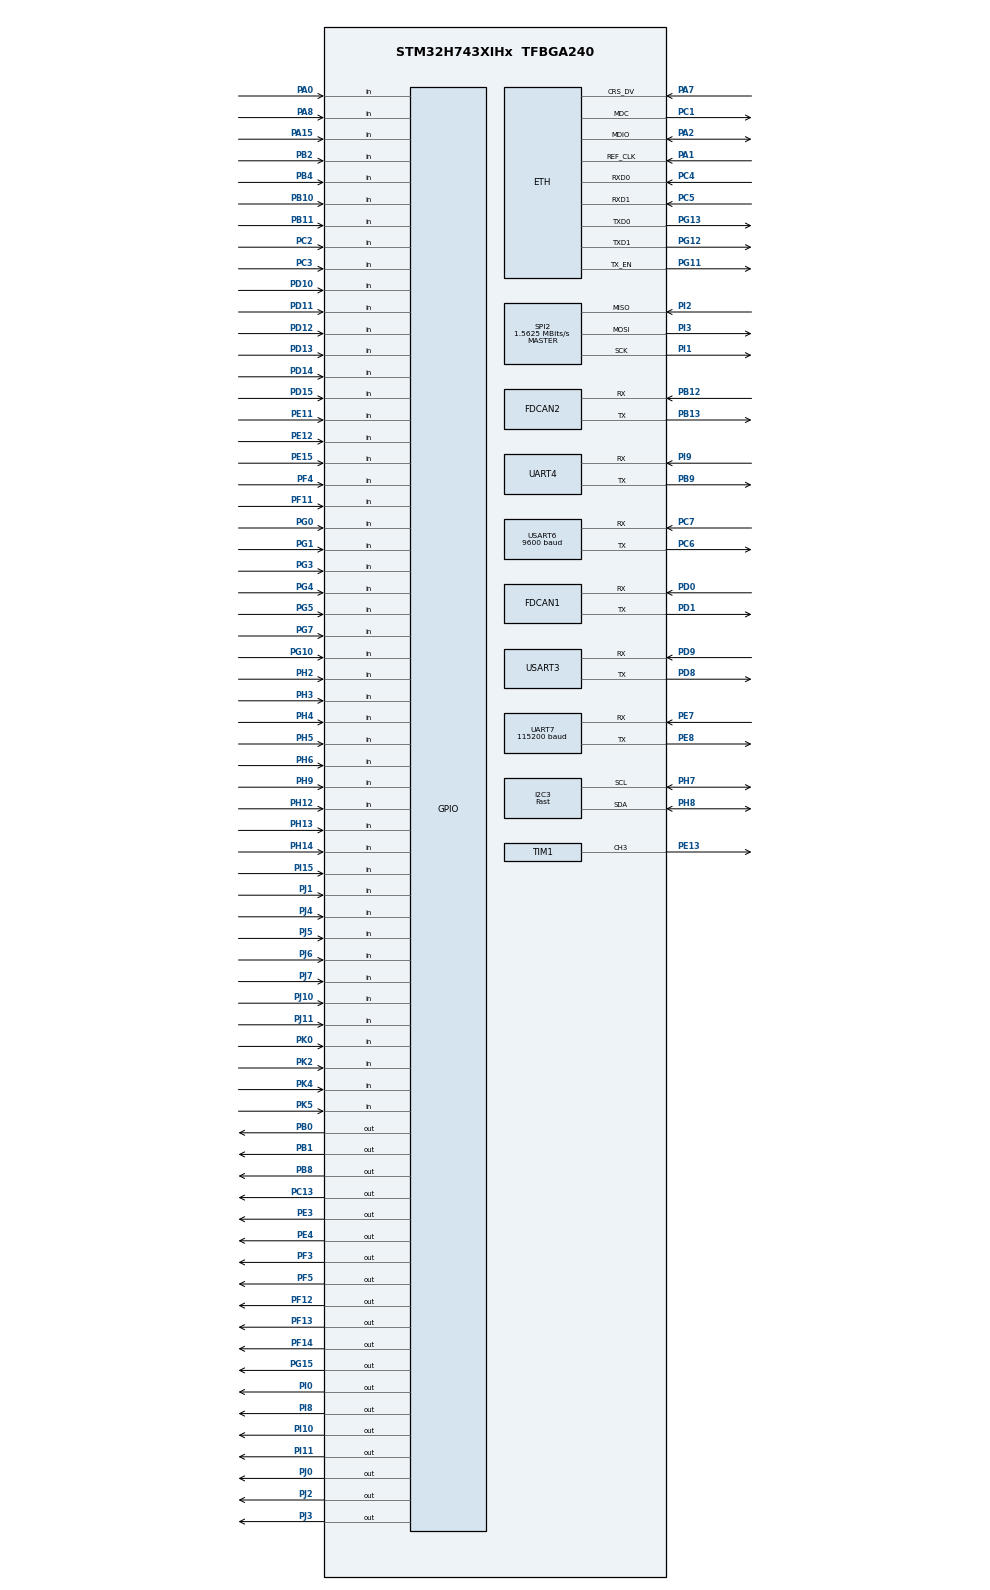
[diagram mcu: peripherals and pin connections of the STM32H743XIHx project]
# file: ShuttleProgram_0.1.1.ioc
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CORTEX_M7.default_mode_Activation=1
Dma.I2C3_TX.0.Direction=DMA_MEMORY_TO_PERIPH
Dma.I2C3_TX.0.EventEnable=DISABLE
Dma.I2C3_TX.0.FIFOMode=DMA_FIFOMODE_DISABLE
Dma.I2C3_TX.0.Instance=DMA1_Stream1
Dma.I2C3_TX.0.MemDataAlignment=DMA_MDATAALIGN_BYTE
Dma.I2C3_TX.0.MemInc=DMA_MINC_ENABLE
Dma.I2C3_TX.0.Mode=DMA_NORMAL
Dma.I2C3_TX.0.PeriphDataAlignment=DMA_PDATAALIGN_BYTE
Dma.I2C3_TX.0.PeriphInc=DMA_PINC_DISABLE
Dma.I2C3_TX.0.Polarity=HAL_DMAMUX_REQ_GEN_RISING
Dma.I2C3_TX.0.Priority=DMA_PRIORITY_LOW
Dma.I2C3_TX.0.RequestNumber=1
Dma.I2C3_TX.0.SignalID=NONE
Dma.I2C3_TX.0.SyncEnable=DISABLE
Dma.I2C3_TX.0.SyncPolarity=HAL_DMAMUX_SYNC_NO_EVENT
Dma.I2C3_TX.0.SyncRequestNumber=1
Dma.I2C3_TX.0.SyncSignalID=NONE
Dma.Request0=I2C3_TX
Dma.Request1=TIM1_CH3
Dma.TIM1_CH3.1.Direction=DMA_MEMORY_TO_PERIPH
Dma.TIM1_CH3.1.EventEnable=DISABLE
Dma.TIM1_CH3.1.FIFOMode=DMA_FIFOMODE_DISABLE
Dma.TIM1_CH3.1.Instance=DMA1_Stream2
Dma.TIM1_CH3.1.MemDataAlignment=DMA_MDATAALIGN_HALFWORD
Dma.TIM1_CH3.1.MemInc=DMA_MINC_ENABLE
Dma.TIM1_CH3.1.Mode=DMA_NORMAL
Dma.TIM1_CH3.1.PeriphDataAlignment=DMA_PDATAALIGN_HALFWORD
Dma.TIM1_CH3.1.PeriphInc=DMA_PINC_DISABLE
Dma.TIM1_CH3.1.Polarity=HAL_DMAMUX_REQ_GEN_RISING
Dma.TIM1_CH3.1.Priority=DMA_PRIORITY_LOW
Dma.TIM1_CH3.1.RequestNumber=1
Dma.TIM1_CH3.1.SignalID=NONE
Dma.TIM1_CH3.1.SyncEnable=DISABLE
Dma.TIM1_CH3.1.SyncPolarity=HAL_DMAMUX_SYNC_NO_EVENT
Dma.TIM1_CH3.1.SyncRequestNumber=1
Dma.TIM1_CH3.1.SyncSignalID=NONE
ETH.MediaInterface=HAL_ETH_RMII_MODE
FDCAN1.CalculateBaudRateNominal=500000
FDCAN1.CalculateTimeBitNominal=2000
FDCAN1.CalculateTimeQuantumNominal=100.0
FDCAN1.ExtFiltersNbr=1
FDCAN1.NominalPrescaler=10
FDCAN1.NominalTimeSeg1=12
FDCAN1.NominalTimeSeg2=7
FDCAN1.ProtocolException=ENABLE
FDCAN1.RxFifo0ElmtsNbr=1
FDCAN1.StdFiltersNbr=1
FDCAN1.TxFifoQueueElmtsNbr=1
FDCAN2.CalculateBaudRateNominal=500000
FDCAN2.CalculateTimeBitNominal=2000
FDCAN2.CalculateTimeQuantumNominal=100.0
FDCAN2.ExtFiltersNbr=1
FDCAN2.NominalPrescaler=10
FDCAN2.NominalTimeSeg1=12
FDCAN2.NominalTimeSeg2=7
FDCAN2.ProtocolException=ENABLE
FDCAN2.RxFifo0ElmtsNbr=1
FDCAN2.StdFiltersNbr=1
FDCAN2.TxFifoQueueElmtsNbr=1
FREERTOS.INCLUDE_xEventGroupSetBitFromISR=1
FREERTOS.Tasks01=mongooseTask,24,2048,StartMongooseTask,Default,NULL,Dynamic,NULL,NULL
FREERTOS.configTOTAL_HEAP_SIZE=131072
FREERTOS.configUSE_NEWLIB_REENTRANT=1
I2C3.I2C_Fall_Time=100
I2C3.I2C_Rise_Time=100
I2C3.I2C_Speed_Mode=I2C_Fast
I2C3.Speed=100
I2C3.Timing=0x5031138C
Mcu.Family=STM32H7
Mcu.Name=STM32H743XIHx
Mcu.Package=TFBGA240
NVIC.DMA1_Stream1_IRQn=true\:5\:0\:false\:false\:true\:true\:false\:true\:true
NVIC.DMA1_Stream2_IRQn=true\:5\:0\:false\:false\:true\:true\:false\:true\:true
NVIC.ETH_IRQn=true\:5\:0\:false\:false\:true\:true\:true\:true\:true
NVIC.FDCAN1_IT0_IRQn=true\:5\:0\:false\:false\:true\:true\:true\:true\:true
NVIC.FDCAN2_IT0_IRQn=true\:5\:0\:false\:false\:true\:true\:true\:true\:true
NVIC.I2C3_EV_IRQn=true\:5\:0\:false\:false\:true\:true\:true\:true\:true
NVIC.PriorityGroup=NVIC_PRIORITYGROUP_4
NVIC.TIM6_DAC_IRQn=true\:15\:0\:false\:false\:true\:false\:false\:true\:true
NVIC.TimeBase=TIM6_DAC_IRQn
NVIC.TimeBaseIP=TIM6
NVIC.UART4_IRQn=true\:5\:0\:false\:false\:true\:true\:true\:true\:true
NVIC.UART7_IRQn=true\:5\:0\:false\:false\:true\:true\:true\:true\:true
NVIC.USART6_IRQn=true\:5\:0\:false\:false\:true\:true\:true\:true\:true
PA0.GPIO_PuPd=GPIO_PULLDOWN
PA0.Signal=GPIO_Input
PA1.GPIO_Speed=GPIO_SPEED_FREQ_VERY_HIGH
PA1.Mode=RMII
PA1.Signal=ETH_REF_CLK
PA15\ (JTDI).Signal=GPIO_Input
PA2.GPIO_Speed=GPIO_SPEED_FREQ_VERY_HIGH
PA2.Mode=RMII
PA2.Signal=ETH_MDIO
PA7.GPIO_Speed=GPIO_SPEED_FREQ_VERY_HIGH
PA7.Mode=RMII
PA7.Signal=ETH_CRS_DV
PA8.Signal=GPIO_Input
PB0.Signal=GPIO_Output
PB1.Signal=GPIO_Output
PB10.GPIO_PuPd=GPIO_PULLDOWN
PB10.Signal=GPIO_Input
PB11.GPIO_PuPd=GPIO_PULLDOWN
PB11.Signal=GPIO_Input
PB12.Mode=FDCAN_Activate
PB12.Signal=FDCAN2_RX
PB13.Mode=FDCAN_Activate
PB13.Signal=FDCAN2_TX
PB2.GPIO_PuPd=GPIO_PULLDOWN
PB2.Signal=GPIO_Input
PB4\ (NJTRST).Signal=GPIO_Input
PB8.Signal=GPIO_Output
PB9.Mode=Asynchronous
PB9.Signal=UART4_TX
PC1.Mode=RMII
PC1.Signal=ETH_MDC
PC13.Signal=GPIO_Output
PC14-OSC32_IN\ (OSC32_IN).Mode=LSE-External-Oscillator
PC14-OSC32_IN\ (OSC32_IN).Signal=RCC_OSC32_IN
PC15-OSC32_OUT\ (OSC32_OUT).Mode=LSE-External-Oscillator
PC15-OSC32_OUT\ (OSC32_OUT).Signal=RCC_OSC32_OUT
PC2.GPIO_PuPd=GPIO_PULLDOWN
PC2.Signal=GPIO_Input
PC3.GPIO_PuPd=GPIO_PULLDOWN
PC3.Signal=GPIO_Input
PC4.GPIO_Speed=GPIO_SPEED_FREQ_VERY_HIGH
PC4.Mode=RMII
PC4.Signal=ETH_RXD0
PC5.GPIO_Speed=GPIO_SPEED_FREQ_VERY_HIGH
PC5.Mode=RMII
PC5.Signal=ETH_RXD1
PC6.Mode=Asynchronous
PC6.Signal=USART6_TX
PC7.Mode=Asynchronous
PC7.Signal=USART6_RX
PD0.Mode=FDCAN_Activate
PD0.Signal=FDCAN1_RX
PD1.Mode=FDCAN_Activate
PD1.Signal=FDCAN1_TX
PD10.Signal=GPIO_Input
PD11.GPIO_PuPd=GPIO_PULLDOWN
PD11.Signal=GPIO_Input
PD12.Signal=GPIO_Input
PD13.Signal=GPIO_Input
PD14.Signal=GPIO_Input
PD15.GPIO_PuPd=GPIO_PULLDOWN
PD15.Signal=GPIO_Input
PD8.Mode=Asynchronous
PD8.Signal=USART3_TX
PD9.Mode=Asynchronous
PD9.Signal=USART3_RX
PE11.Signal=GPIO_Input
PE12.GPIO_PuPd=GPIO_PULLDOWN
PE12.Signal=GPIO_Input
PE13.Signal=S_TIM1_CH3
PE15.Signal=GPIO_Input
PE3.Signal=GPIO_Output
PE4.Signal=GPIO_Output
PE7.Mode=Asynchronous
PE7.Signal=UART7_RX
PE8.Mode=Asynchronous
PE8.Signal=UART7_TX
PF11.GPIO_PuPd=GPIO_PULLDOWN
PF11.Signal=GPIO_Input
PF12.Signal=GPIO_Output
PF13.Signal=GPIO_Output
PF14.Signal=GPIO_Output
PF3.Signal=GPIO_Output
PF4.GPIO_PuPd=GPIO_PULLDOWN
PF4.Signal=GPIO_Input
PF5.Signal=GPIO_Output
PG0.GPIO_PuPd=GPIO_PULLDOWN
PG0.Signal=GPIO_Input
PG1.GPIO_PuPd=GPIO_PULLDOWN
PG1.Signal=GPIO_Input
PG10.GPIO_PuPd=GPIO_PULLDOWN
PG10.Signal=GPIO_Input
PG11.GPIO_Speed=GPIO_SPEED_FREQ_VERY_HIGH
PG11.Mode=RMII
PG11.Signal=ETH_TX_EN
PG12.GPIO_Speed=GPIO_SPEED_FREQ_VERY_HIGH
PG12.Mode=RMII
PG12.Signal=ETH_TXD1
PG13.GPIO_Speed=GPIO_SPEED_FREQ_VERY_HIGH
PG13.Mode=RMII
PG13.Signal=ETH_TXD0
PG15.Signal=GPIO_Output
PG3.Signal=GPIO_Input
PG4.Signal=GPIO_Input
PG5.Signal=GPIO_Input
PG7.Signal=GPIO_Input
PH0-OSC_IN\ (PH0).Mode=HSE-External-Oscillator
PH0-OSC_IN\ (PH0).Signal=RCC_OSC_IN
PH1-OSC_OUT\ (PH1).Mode=HSE-External-Oscillator
PH1-OSC_OUT\ (PH1).Signal=RCC_OSC_OUT
PH12.GPIO_PuPd=GPIO_PULLDOWN
PH12.Signal=GPIO_Input
PH13.Signal=GPIO_Input
PH14.Signal=GPIO_Input
PH2.GPIO_PuPd=GPIO_PULLDOWN
PH2.Signal=GPIO_Input
PH3.GPIO_PuPd=GPIO_PULLDOWN
PH3.Signal=GPIO_Input
PH4.GPIO_PuPd=GPIO_PULLDOWN
PH4.Signal=GPIO_Input
PH5.GPIO_PuPd=GPIO_PULLDOWN
PH5.Signal=GPIO_Input
PH6.GPIO_PuPd=GPIO_PULLDOWN
PH6.Signal=GPIO_Input
PH7.Mode=I2C
PH7.Signal=I2C3_SCL
PH8.Mode=I2C
PH8.Signal=I2C3_SDA
PH9.GPIO_PuPd=GPIO_PULLDOWN
PH9.Signal=GPIO_Input
PI0.Signal=GPIO_Output
PI1.Mode=Full_Duplex_Master
PI1.Signal=SPI2_SCK
PI10.Signal=GPIO_Output
PI11.Signal=GPIO_Output
PI15.GPIO_PuPd=GPIO_PULLDOWN
PI15.Signal=GPIO_Input
PI2.Mode=Full_Duplex_Master
PI2.Signal=SPI2_MISO
PI3.Mode=Full_Duplex_Master
PI3.Signal=SPI2_MOSI
PI8.Signal=GPIO_Output
PI9.Mode=Asynchronous
PI9.Signal=UART4_RX
PJ0.Signal=GPIO_Output
PJ1.GPIO_PuPd=GPIO_PULLDOWN
PJ1.Signal=GPIO_Input
PJ10.Signal=GPIO_Input
PJ11.Signal=GPIO_Input
PJ2.Signal=GPIO_Output
PJ3.Signal=GPIO_Output
PJ4.GPIO_PuPd=GPIO_PULLDOWN
PJ4.Signal=GPIO_Input
PJ5.GPIO_PuPd=GPIO_PULLDOWN
PJ5.Signal=GPIO_Input
PJ6.GPIO_PuPd=GPIO_PULLDOWN
PJ6.Signal=GPIO_Input
PJ7.Signal=GPIO_Input
PK0.Signal=GPIO_Input
PK2.Signal=GPIO_Input
PK4.Signal=GPIO_Input
PK5.GPIO_PuPd=GPIO_PULLDOWN
PK5.Signal=GPIO_Input
ProjectManager.HeapSize=0x200
ProjectManager.StackSize=0x400
ProjectManager.TargetToolchain=STM32CubeIDE
RCC.ADCFreq_Value=50390625
RCC.APB1Freq_Value=100000000
RCC.APB2Freq_Value=100000000
RCC.APB3Freq_Value=100000000
RCC.APB4Freq_Value=100000000
RCC.CortexFreq_Value=400000000
RCC.D1PPRE=RCC_APB3_DIV2
RCC.D2PPRE1=RCC_APB1_DIV2
RCC.D2PPRE2=RCC_APB2_DIV2
RCC.D3PPRE=RCC_APB4_DIV2
RCC.DIVM1=2
RCC.DIVN1=64
RCC.DIVQ1=8
RCC.HCLKFreq_Value=200000000
RCC.HPRE=RCC_HCLK_DIV2
RCC.PLLSourceVirtual=RCC_PLLSOURCE_HSE
RCC.PWR_Regulator_Voltage_Scale=PWR_REGULATOR_VOLTAGE_SCALE0
RCC.SYSCLKFreq_VALUE=400000000
RCC.SYSCLKSource=RCC_SYSCLKSOURCE_PLLCLK
RCC.Spi45ClockSelection=RCC_SPI45CLKSOURCE_HSI
RCC.SupplySource=PWR_LDO_SUPPLY
RCC.USBFreq_Value=100000000
SH.S_TIM1_CH3.0=TIM1_CH3,PWM Generation3 CH3
SPI2.BaudRatePrescaler=SPI_BAUDRATEPRESCALER_64
SPI2.CLKPhase=SPI_PHASE_2EDGE
SPI2.CLKPolarity=SPI_POLARITY_HIGH
SPI2.CalculateBaudRate=1.5625 MBits/s
SPI2.DataSize=SPI_DATASIZE_8BIT
SPI2.Direction=SPI_DIRECTION_2LINES
SPI2.Mode=SPI_MODE_MASTER
SPI2.VirtualType=VM_MASTER
TIM1.Channel-PWM\ Generation3\ CH3=TIM_CHANNEL_3
TIM1.Period=250-1
UART7.BaudRate=115200
USART3.VirtualMode-Asynchronous=VM_ASYNC
USART6.BaudRate=9600
USART6.VirtualMode-Asynchronous=VM_ASYNC
VP_FREERTOS_VS_CMSIS_V2.Mode=CMSIS_V2
VP_MEMORYMAP_VS_MEMORYMAP.Mode=CurAppReg
VP_RNG_VS_RNG.Mode=RNG_Activate
VP_SYS_VS_tim6.Mode=TIM6
VP_TIM1_VS_ClockSourceINT.Mode=Internal
board=custom

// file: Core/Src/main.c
/* USER CODE BEGIN Header */
/**
  ******************************************************************************
  * @file           : main.c
  * @brief          : Main program body
  ******************************************************************************
  * @attention
  *
  * Copyright (c) 2025 STMicroelectronics.
  * All rights reserved.
  *
  * This software is licensed under terms that can be found in the LICENSE file
  * in the root directory of this software component.
  * If no LICENSE file comes with this software, it is provided AS-IS.
  *
  ******************************************************************************
  */
/* USER CODE END Header */
#include "main.h"
#include "string.h"
#include "cmsis_os.h"

/* USER CODE BEGIN Includes */
#include "mongoose_glue.h"
#include "database.h"
#include "sensorSignal.h"
#include "manual.h"
#include "auto.h"
#include "update_data.h"
#include "safety.h"
#include "display.h"
#include "hydraulic.h"
/* USER CODE END Includes */

#if defined ( __ICCARM__ ) /*!< IAR Compiler */
#pragma location=0x30000000
ETH_DMADescTypeDef  DMARxDscrTab[ETH_RX_DESC_CNT]; /* Ethernet Rx DMA Descriptors */
#pragma location=0x30000080
ETH_DMADescTypeDef  DMATxDscrTab[ETH_TX_DESC_CNT]; /* Ethernet Tx DMA Descriptors */

#elif defined ( __CC_ARM )  /* MDK ARM Compiler */

__attribute__((at(0x30000000))) ETH_DMADescTypeDef  DMARxDscrTab[ETH_RX_DESC_CNT]; /* Ethernet Rx DMA Descriptors */
__attribute__((at(0x30000080))) ETH_DMADescTypeDef  DMATxDscrTab[ETH_TX_DESC_CNT]; /* Ethernet Tx DMA Descriptors */

#elif defined ( __GNUC__ ) /* GNU Compiler */

ETH_DMADescTypeDef DMARxDscrTab[ETH_RX_DESC_CNT] __attribute__((section(".RxDescripSection"))); /* Ethernet Rx DMA Descriptors */
ETH_DMADescTypeDef DMATxDscrTab[ETH_TX_DESC_CNT] __attribute__((section(".TxDescripSection")));   /* Ethernet Tx DMA Descriptors */
#endif

ETH_TxPacketConfig TxConfig;

ETH_HandleTypeDef heth;

FDCAN_HandleTypeDef hfdcan1;
FDCAN_HandleTypeDef hfdcan2;

I2C_HandleTypeDef hi2c3;
DMA_HandleTypeDef hdma_i2c3_tx;

RNG_HandleTypeDef hrng;

SPI_HandleTypeDef hspi2;

TIM_HandleTypeDef htim1;
DMA_HandleTypeDef hdma_tim1_ch3;

UART_HandleTypeDef huart4;
UART_HandleTypeDef huart7;
UART_HandleTypeDef huart3;
UART_HandleTypeDef huart6;

/* Definitions for mongooseTask */
osThreadId_t mongooseTaskHandle;
const osThreadAttr_t mongooseTask_attributes = {
  .name = "mongooseTask",
  .stack_size = 2048 * 4,
  .priority = (osPriority_t) osPriorityNormal,
};

void SystemClock_Config(void);
static void MPU_Config(void);
static void MX_GPIO_Init(void);
static void MX_DMA_Init(void);
static void MX_RNG_Init(void);
static void MX_USART3_UART_Init(void);
static void MX_ETH_Init(void);
static void MX_FDCAN1_Init(void);
static void MX_UART7_Init(void);
static void MX_I2C3_Init(void);
static void MX_TIM1_Init(void);
static void MX_USART6_UART_Init(void);
static void MX_SPI2_Init(void);
static void MX_UART4_Init(void);
static void MX_FDCAN2_Init(void);
void StartMongooseTask(void *argument);

/* USER CODE BEGIN PFP */
void selectMode(uint8_t sw)
{
	static bool run_one = false ;
	if(!run_one){
		manualTaskInit();
		autoTaskInit() ;
		dataUpdateTaskInit();
		safetyTaskInit();
		hydraulicTaskInit();
		run_one = true ;
		return ;
	}
	if(sw)
	{
		manualTaskSupend();
		autoTaskResume() ;
	}else
	{
		autoTaskSupend();
		manualTaskResume();
	}
	static uint8_t current_mode;
	if (current_mode != sw) {
		ResetOutput();
		SetSpeed(0, SetSpeedPDO[0]);
		current_mode = sw;
	}

}
/* USER CODE END PFP */

/* USER CODE BEGIN 0 */
int _write(int fd, unsigned char *buf, int len) {
  if (fd == 1 || fd == 2) {                     // stdout or stderr ?
    HAL_UART_Transmit(&huart3, buf, len, 999);  // Print to the UART
  }
  return len;
}
bool mg_random(void *buf, size_t len) {  // Use on-board RNG
  for (size_t n = 0; n < len; n += sizeof(uint32_t)) {
    uint32_t r;
    HAL_RNG_GenerateRandomNumber(&hrng, &r);
    memcpy((char *) buf + n, &r, n + sizeof(r) > len ? len - n : sizeof(r));
  }
  return true; // TODO(): ensure successful RNG init, then return on false above
}
/* USER CODE END 0 */

int main(void)
{

  /* MPU Configuration--------------------------------------------------------*/
  MPU_Config();

  /* MCU Configuration--------------------------------------------------------*/

  /* Reset of all peripherals, Initializes the Flash interface and the Systick. */
  HAL_Init();

  /* Configure the system clock */
  SystemClock_Config();

  /* Initialize all configured peripherals */
  MX_GPIO_Init();
  MX_DMA_Init();
  MX_RNG_Init();
  MX_USART3_UART_Init();
  MX_ETH_Init();
  MX_FDCAN1_Init();
  MX_UART7_Init();
  MX_I2C3_Init();
  MX_TIM1_Init();
  MX_USART6_UART_Init();
  MX_SPI2_Init();
  MX_UART4_Init();
  MX_FDCAN2_Init();
  /* USER CODE BEGIN 2 */
  switch_mode_register_callback(selectMode);

  /* USER CODE END 2 */

  /* Init scheduler */
  osKernelInitialize();

  /* USER CODE BEGIN RTOS_QUEUES */
  /* add queues, ... */

  /*
   * Priority task default
   * Auto task-------------osPriorityNormal3
   * Manual task-----------osPriorityNormal3
   * inforUpdatetask-------osPriorityNormal2
   * displayTaskHandle-----osPriorityNormal1
   * StartMongooseTask-----------osPriorityNormal
   * DataEthTask-----------osPriorityAboveNormal
   * IOTaskHandle----------osPriorityAboveNormal1
   * hydraulicTaskAttr-----osPriorityAboveNormal2
   * safetyTaskHandle------osPriorityAboveNormal3
   * qrTask----------------osPriorityISR
   */
  displayInit();
  databaseInit();
  sensorTaskInit();
  /* USER CODE END RTOS_QUEUES */

  /* Create the thread(s) */
  /* creation of mongooseTask */
  mongooseTaskHandle = osThreadNew(StartMongooseTask, NULL, &mongooseTask_attributes);

  /* Start scheduler */
  osKernelStart();

  /* We should never get here as control is now taken by the scheduler */

  /* Infinite loop */
  while (1)
  {

  }
}

void SystemClock_Config(void)
{
  RCC_OscInitTypeDef RCC_OscInitStruct = {0};
  RCC_ClkInitTypeDef RCC_ClkInitStruct = {0};

  /** Supply configuration update enable
  */
  HAL_PWREx_ConfigSupply(PWR_LDO_SUPPLY);

  /** Configure the main internal regulator output voltage
  */
  __HAL_PWR_VOLTAGESCALING_CONFIG(PWR_REGULATOR_VOLTAGE_SCALE0);

  while(!__HAL_PWR_GET_FLAG(PWR_FLAG_VOSRDY)) {}

  /** Initializes the RCC Oscillators according to the specified parameters
  * in the RCC_OscInitTypeDef structure.
  */
  RCC_OscInitStruct.OscillatorType = RCC_OSCILLATORTYPE_HSI48|RCC_OSCILLATORTYPE_HSE;
  RCC_OscInitStruct.HSEState = RCC_HSE_ON;
  RCC_OscInitStruct.HSI48State = RCC_HSI48_ON;
  RCC_OscInitStruct.PLL.PLLState = RCC_PLL_ON;
  RCC_OscInitStruct.PLL.PLLSource = RCC_PLLSOURCE_HSE;
  RCC_OscInitStruct.PLL.PLLM = 2;
  RCC_OscInitStruct.PLL.PLLN = 64;
  RCC_OscInitStruct.PLL.PLLP = 2;
  RCC_OscInitStruct.PLL.PLLQ = 8;
  RCC_OscInitStruct.PLL.PLLR = 2;
  RCC_OscInitStruct.PLL.PLLRGE = RCC_PLL1VCIRANGE_3;
  RCC_OscInitStruct.PLL.PLLVCOSEL = RCC_PLL1VCOWIDE;
  RCC_OscInitStruct.PLL.PLLFRACN = 0;
  if (HAL_RCC_OscConfig(&RCC_OscInitStruct) != HAL_OK)
  {
    Error_Handler();
  }

  /** Initializes the CPU, AHB and APB buses clocks
  */
  RCC_ClkInitStruct.ClockType = RCC_CLOCKTYPE_HCLK|RCC_CLOCKTYPE_SYSCLK
                              |RCC_CLOCKTYPE_PCLK1|RCC_CLOCKTYPE_PCLK2
                              |RCC_CLOCKTYPE_D3PCLK1|RCC_CLOCKTYPE_D1PCLK1;
  RCC_ClkInitStruct.SYSCLKSource = RCC_SYSCLKSOURCE_PLLCLK;
  RCC_ClkInitStruct.SYSCLKDivider = RCC_SYSCLK_DIV1;
  RCC_ClkInitStruct.AHBCLKDivider = RCC_HCLK_DIV2;
  RCC_ClkInitStruct.APB3CLKDivider = RCC_APB3_DIV2;
  RCC_ClkInitStruct.APB1CLKDivider = RCC_APB1_DIV2;
  RCC_ClkInitStruct.APB2CLKDivider = RCC_APB2_DIV2;
  RCC_ClkInitStruct.APB4CLKDivider = RCC_APB4_DIV2;

  if (HAL_RCC_ClockConfig(&RCC_ClkInitStruct, FLASH_LATENCY_2) != HAL_OK)
  {
    Error_Handler();
  }
}

static void MX_ETH_Init(void)
{

   static uint8_t MACAddr[6];

  heth.Instance = ETH;
  MACAddr[0] = 0x00;
  MACAddr[1] = 0x80;
  MACAddr[2] = 0xE1;
  MACAddr[3] = 0x00;
  MACAddr[4] = 0x00;
  MACAddr[5] = 0x00;
  heth.Init.MACAddr = &MACAddr[0];
  heth.Init.MediaInterface = HAL_ETH_RMII_MODE;
  heth.Init.TxDesc = DMATxDscrTab;
  heth.Init.RxDesc = DMARxDscrTab;
  heth.Init.RxBuffLen = 1536;

  if (HAL_ETH_Init(&heth) != HAL_OK)
  {
    Error_Handler();
  }

  memset(&TxConfig, 0 , sizeof(ETH_TxPacketConfig));
  TxConfig.Attributes = ETH_TX_PACKETS_FEATURES_CSUM | ETH_TX_PACKETS_FEATURES_CRCPAD;
  TxConfig.ChecksumCtrl = ETH_CHECKSUM_IPHDR_PAYLOAD_INSERT_PHDR_CALC;
  TxConfig.CRCPadCtrl = ETH_CRC_PAD_INSERT;

}

static void MX_FDCAN1_Init(void)
{

  hfdcan1.Instance = FDCAN1;
  hfdcan1.Init.FrameFormat = FDCAN_FRAME_CLASSIC;
  hfdcan1.Init.Mode = FDCAN_MODE_NORMAL;
  hfdcan1.Init.AutoRetransmission = DISABLE;
  hfdcan1.Init.TransmitPause = DISABLE;
  hfdcan1.Init.ProtocolException = ENABLE;
  hfdcan1.Init.NominalPrescaler = 10;
  hfdcan1.Init.NominalSyncJumpWidth = 1;
  hfdcan1.Init.NominalTimeSeg1 = 12;
  hfdcan1.Init.NominalTimeSeg2 = 7;
  hfdcan1.Init.DataPrescaler = 1;
  hfdcan1.Init.DataSyncJumpWidth = 1;
  hfdcan1.Init.DataTimeSeg1 = 1;
  hfdcan1.Init.DataTimeSeg2 = 1;
  hfdcan1.Init.MessageRAMOffset = 0;
  hfdcan1.Init.StdFiltersNbr = 1;
  hfdcan1.Init.ExtFiltersNbr = 1;
  hfdcan1.Init.RxFifo0ElmtsNbr = 1;
  hfdcan1.Init.RxFifo0ElmtSize = FDCAN_DATA_BYTES_8;
  hfdcan1.Init.RxFifo1ElmtsNbr = 0;
  hfdcan1.Init.RxFifo1ElmtSize = FDCAN_DATA_BYTES_8;
  hfdcan1.Init.RxBuffersNbr = 0;
  hfdcan1.Init.RxBufferSize = FDCAN_DATA_BYTES_8;
  hfdcan1.Init.TxEventsNbr = 0;
  hfdcan1.Init.TxBuffersNbr = 0;
  hfdcan1.Init.TxFifoQueueElmtsNbr = 1;
  hfdcan1.Init.TxFifoQueueMode = FDCAN_TX_FIFO_OPERATION;
  hfdcan1.Init.TxElmtSize = FDCAN_DATA_BYTES_8;
  if (HAL_FDCAN_Init(&hfdcan1) != HAL_OK)
  {
    Error_Handler();
  }

}

static void MX_FDCAN2_Init(void)
{

  hfdcan2.Instance = FDCAN2;
  hfdcan2.Init.FrameFormat = FDCAN_FRAME_CLASSIC;
  hfdcan2.Init.Mode = FDCAN_MODE_NORMAL;
  hfdcan2.Init.AutoRetransmission = DISABLE;
  hfdcan2.Init.TransmitPause = DISABLE;
  hfdcan2.Init.ProtocolException = ENABLE;
  hfdcan2.Init.NominalPrescaler = 10;
  hfdcan2.Init.NominalSyncJumpWidth = 1;
  hfdcan2.Init.NominalTimeSeg1 = 12;
  hfdcan2.Init.NominalTimeSeg2 = 7;
  hfdcan2.Init.DataPrescaler = 1;
  hfdcan2.Init.DataSyncJumpWidth = 1;
  hfdcan2.Init.DataTimeSeg1 = 1;
  hfdcan2.Init.DataTimeSeg2 = 1;
  hfdcan2.Init.MessageRAMOffset = 0;
  hfdcan2.Init.StdFiltersNbr = 1;
  hfdcan2.Init.ExtFiltersNbr = 1;
  hfdcan2.Init.RxFifo0ElmtsNbr = 1;
  hfdcan2.Init.RxFifo0ElmtSize = FDCAN_DATA_BYTES_8;
  hfdcan2.Init.RxFifo1ElmtsNbr = 0;
  hfdcan2.Init.RxFifo1ElmtSize = FDCAN_DATA_BYTES_8;
  hfdcan2.Init.RxBuffersNbr = 0;
  hfdcan2.Init.RxBufferSize = FDCAN_DATA_BYTES_8;
  hfdcan2.Init.TxEventsNbr = 0;
  hfdcan2.Init.TxBuffersNbr = 0;
  hfdcan2.Init.TxFifoQueueElmtsNbr = 1;
  hfdcan2.Init.TxFifoQueueMode = FDCAN_TX_FIFO_OPERATION;
  hfdcan2.Init.TxElmtSize = FDCAN_DATA_BYTES_8;
  if (HAL_FDCAN_Init(&hfdcan2) != HAL_OK)
  {
    Error_Handler();
  }

}

static void MX_I2C3_Init(void)
{

  hi2c3.Instance = I2C3;
  hi2c3.Init.Timing = 0x5031138C;
  hi2c3.Init.OwnAddress1 = 0;
  hi2c3.Init.AddressingMode = I2C_ADDRESSINGMODE_7BIT;
  hi2c3.Init.DualAddressMode = I2C_DUALADDRESS_DISABLE;
  hi2c3.Init.OwnAddress2 = 0;
  hi2c3.Init.OwnAddress2Masks = I2C_OA2_NOMASK;
  hi2c3.Init.GeneralCallMode = I2C_GENERALCALL_DISABLE;
  hi2c3.Init.NoStretchMode = I2C_NOSTRETCH_DISABLE;
  if (HAL_I2C_Init(&hi2c3) != HAL_OK)
  {
    Error_Handler();
  }

  /** Configure Analogue filter
  */
  if (HAL_I2CEx_ConfigAnalogFilter(&hi2c3, I2C_ANALOGFILTER_ENABLE) != HAL_OK)
  {
    Error_Handler();
  }

  /** Configure Digital filter
  */
  if (HAL_I2CEx_ConfigDigitalFilter(&hi2c3, 0) != HAL_OK)
  {
    Error_Handler();
  }

}

static void MX_RNG_Init(void)
{

  hrng.Instance = RNG;
  hrng.Init.ClockErrorDetection = RNG_CED_ENABLE;
  if (HAL_RNG_Init(&hrng) != HAL_OK)
  {
    Error_Handler();
  }

}

static void MX_SPI2_Init(void)
{

  /* SPI2 parameter configuration*/
  hspi2.Instance = SPI2;
  hspi2.Init.Mode = SPI_MODE_MASTER;
  hspi2.Init.Direction = SPI_DIRECTION_2LINES;
  hspi2.Init.DataSize = SPI_DATASIZE_8BIT;
  hspi2.Init.CLKPolarity = SPI_POLARITY_HIGH;
  hspi2.Init.CLKPhase = SPI_PHASE_2EDGE;
  hspi2.Init.NSS = SPI_NSS_SOFT;
  hspi2.Init.BaudRatePrescaler = SPI_BAUDRATEPRESCALER_64;
  hspi2.Init.FirstBit = SPI_FIRSTBIT_MSB;
  hspi2.Init.TIMode = SPI_TIMODE_DISABLE;
  hspi2.Init.CRCCalculation = SPI_CRCCALCULATION_DISABLE;
  hspi2.Init.CRCPolynomial = 0x0;
  hspi2.Init.NSSPMode = SPI_NSS_PULSE_ENABLE;
  hspi2.Init.NSSPolarity = SPI_NSS_POLARITY_LOW;
  hspi2.Init.FifoThreshold = SPI_FIFO_THRESHOLD_01DATA;
  hspi2.Init.TxCRCInitializationPattern = SPI_CRC_INITIALIZATION_ALL_ZERO_PATTERN;
  hspi2.Init.RxCRCInitializationPattern = SPI_CRC_INITIALIZATION_ALL_ZERO_PATTERN;
  hspi2.Init.MasterSSIdleness = SPI_MASTER_SS_IDLENESS_00CYCLE;
  hspi2.Init.MasterInterDataIdleness = SPI_MASTER_INTERDATA_IDLENESS_00CYCLE;
  hspi2.Init.MasterReceiverAutoSusp = SPI_MASTER_RX_AUTOSUSP_DISABLE;
  hspi2.Init.MasterKeepIOState = SPI_MASTER_KEEP_IO_STATE_DISABLE;
  hspi2.Init.IOSwap = SPI_IO_SWAP_DISABLE;
  if (HAL_SPI_Init(&hspi2) != HAL_OK)
  {
    Error_Handler();
  }

}

static void MX_TIM1_Init(void)
{

  TIM_ClockConfigTypeDef sClockSourceConfig = {0};
  TIM_MasterConfigTypeDef sMasterConfig = {0};
  TIM_OC_InitTypeDef sConfigOC = {0};
  TIM_BreakDeadTimeConfigTypeDef sBreakDeadTimeConfig = {0};

  htim1.Instance = TIM1;
  htim1.Init.Prescaler = 0;
  htim1.Init.CounterMode = TIM_COUNTERMODE_UP;
  htim1.Init.Period = 250-1;
  htim1.Init.ClockDivision = TIM_CLOCKDIVISION_DIV1;
  htim1.Init.RepetitionCounter = 0;
  htim1.Init.AutoReloadPreload = TIM_AUTORELOAD_PRELOAD_DISABLE;
  if (HAL_TIM_Base_Init(&htim1) != HAL_OK)
  {
    Error_Handler();
  }
  sClockSourceConfig.ClockSource = TIM_CLOCKSOURCE_INTERNAL;
  if (HAL_TIM_ConfigClockSource(&htim1, &sClockSourceConfig) != HAL_OK)
  {
    Error_Handler();
  }
  if (HAL_TIM_PWM_Init(&htim1) != HAL_OK)
  {
    Error_Handler();
  }
  sMasterConfig.MasterOutputTrigger = TIM_TRGO_RESET;
  sMasterConfig.MasterOutputTrigger2 = TIM_TRGO2_RESET;
  sMasterConfig.MasterSlaveMode = TIM_MASTERSLAVEMODE_DISABLE;
  if (HAL_TIMEx_MasterConfigSynchronization(&htim1, &sMasterConfig) != HAL_OK)
  {
    Error_Handler();
  }
  sConfigOC.OCMode = TIM_OCMODE_PWM1;
  sConfigOC.Pulse = 0;
  sConfigOC.OCPolarity = TIM_OCPOLARITY_HIGH;
  sConfigOC.OCNPolarity = TIM_OCNPOLARITY_HIGH;
  sConfigOC.OCFastMode = TIM_OCFAST_DISABLE;
  sConfigOC.OCIdleState = TIM_OCIDLESTATE_RESET;
  sConfigOC.OCNIdleState = TIM_OCNIDLESTATE_RESET;
  if (HAL_TIM_PWM_ConfigChannel(&htim1, &sConfigOC, TIM_CHANNEL_3) != HAL_OK)
  {
    Error_Handler();
  }
  sBreakDeadTimeConfig.OffStateRunMode = TIM_OSSR_DISABLE;
  sBreakDeadTimeConfig.OffStateIDLEMode = TIM_OSSI_DISABLE;
  sBreakDeadTimeConfig.LockLevel = TIM_LOCKLEVEL_OFF;
  sBreakDeadTimeConfig.DeadTime = 0;
  sBreakDeadTimeConfig.BreakState = TIM_BREAK_DISABLE;
  sBreakDeadTimeConfig.BreakPolarity = TIM_BREAKPOLARITY_HIGH;
  sBreakDeadTimeConfig.BreakFilter = 0;
  sBreakDeadTimeConfig.Break2State = TIM_BREAK2_DISABLE;
  sBreakDeadTimeConfig.Break2Polarity = TIM_BREAK2POLARITY_HIGH;
  sBreakDeadTimeConfig.Break2Filter = 0;
  sBreakDeadTimeConfig.AutomaticOutput = TIM_AUTOMATICOUTPUT_DISABLE;
  if (HAL_TIMEx_ConfigBreakDeadTime(&htim1, &sBreakDeadTimeConfig) != HAL_OK)
  {
    Error_Handler();
  }
  HAL_TIM_MspPostInit(&htim1);

}

static void MX_UART4_Init(void)
{

  huart4.Instance = UART4;
  huart4.Init.BaudRate = 115200;
  huart4.Init.WordLength = UART_WORDLENGTH_8B;
  huart4.Init.StopBits = UART_STOPBITS_1;
  huart4.Init.Parity = UART_PARITY_NONE;
  huart4.Init.Mode = UART_MODE_TX_RX;
  huart4.Init.HwFlowCtl = UART_HWCONTROL_NONE;
  huart4.Init.OverSampling = UART_OVERSAMPLING_16;
  huart4.Init.OneBitSampling = UART_ONE_BIT_SAMPLE_DISABLE;
  huart4.Init.ClockPrescaler = UART_PRESCALER_DIV1;
  huart4.AdvancedInit.AdvFeatureInit = UART_ADVFEATURE_NO_INIT;
  if (HAL_UART_Init(&huart4) != HAL_OK)
  {
    Error_Handler();
  }
  if (HAL_UARTEx_SetTxFifoThreshold(&huart4, UART_TXFIFO_THRESHOLD_1_8) != HAL_OK)
  {
    Error_Handler();
  }
  if (HAL_UARTEx_SetRxFifoThreshold(&huart4, UART_RXFIFO_THRESHOLD_1_8) != HAL_OK)
  {
    Error_Handler();
  }
  if (HAL_UARTEx_DisableFifoMode(&huart4) != HAL_OK)
  {
    Error_Handler();
  }

}

static void MX_UART7_Init(void)
{

  huart7.Instance = UART7;
  huart7.Init.BaudRate = 115200;
  huart7.Init.WordLength = UART_WORDLENGTH_8B;
  huart7.Init.StopBits = UART_STOPBITS_1;
  huart7.Init.Parity = UART_PARITY_NONE;
  huart7.Init.Mode = UART_MODE_TX_RX;
  huart7.Init.HwFlowCtl = UART_HWCONTROL_NONE;
  huart7.Init.OverSampling = UART_OVERSAMPLING_16;
  huart7.Init.OneBitSampling = UART_ONE_BIT_SAMPLE_DISABLE;
  huart7.Init.ClockPrescaler = UART_PRESCALER_DIV1;
  huart7.AdvancedInit.AdvFeatureInit = UART_ADVFEATURE_NO_INIT;
  if (HAL_UART_Init(&huart7) != HAL_OK)
  {
    Error_Handler();
  }
  if (HAL_UARTEx_SetTxFifoThreshold(&huart7, UART_TXFIFO_THRESHOLD_1_8) != HAL_OK)
  {
    Error_Handler();
  }
  if (HAL_UARTEx_SetRxFifoThreshold(&huart7, UART_RXFIFO_THRESHOLD_1_8) != HAL_OK)
  {
    Error_Handler();
  }
  if (HAL_UARTEx_DisableFifoMode(&huart7) != HAL_OK)
  {
    Error_Handler();
  }

}

static void MX_USART3_UART_Init(void)
{

  huart3.Instance = USART3;
  huart3.Init.BaudRate = 115200;
  huart3.Init.WordLength = UART_WORDLENGTH_8B;
  huart3.Init.StopBits = UART_STOPBITS_1;
  huart3.Init.Parity = UART_PARITY_NONE;
  huart3.Init.Mode = UART_MODE_TX_RX;
  huart3.Init.HwFlowCtl = UART_HWCONTROL_NONE;
  huart3.Init.OverSampling = UART_OVERSAMPLING_16;
  huart3.Init.OneBitSampling = UART_ONE_BIT_SAMPLE_DISABLE;
  huart3.Init.ClockPrescaler = UART_PRESCALER_DIV1;
  huart3.AdvancedInit.AdvFeatureInit = UART_ADVFEATURE_NO_INIT;
  if (HAL_UART_Init(&huart3) != HAL_OK)
  {
    Error_Handler();
  }
  if (HAL_UARTEx_SetTxFifoThreshold(&huart3, UART_TXFIFO_THRESHOLD_1_8) != HAL_OK)
  {
    Error_Handler();
  }
  if (HAL_UARTEx_SetRxFifoThreshold(&huart3, UART_RXFIFO_THRESHOLD_1_8) != HAL_OK)
  {
    Error_Handler();
  }
  if (HAL_UARTEx_DisableFifoMode(&huart3) != HAL_OK)
  {
    Error_Handler();
  }

}

static void MX_USART6_UART_Init(void)
{

  huart6.Instance = USART6;
  huart6.Init.BaudRate = 9600;
  huart6.Init.WordLength = UART_WORDLENGTH_8B;
  huart6.Init.StopBits = UART_STOPBITS_1;
  huart6.Init.Parity = UART_PARITY_NONE;
  huart6.Init.Mode = UART_MODE_TX_RX;
  huart6.Init.HwFlowCtl = UART_HWCONTROL_NONE;
  huart6.Init.OverSampling = UART_OVERSAMPLING_16;
  huart6.Init.OneBitSampling = UART_ONE_BIT_SAMPLE_DISABLE;
  huart6.Init.ClockPrescaler = UART_PRESCALER_DIV1;
  huart6.AdvancedInit.AdvFeatureInit = UART_ADVFEATURE_NO_INIT;
  if (HAL_UART_Init(&huart6) != HAL_OK)
  {
    Error_Handler();
  }
  if (HAL_UARTEx_SetTxFifoThreshold(&huart6, UART_TXFIFO_THRESHOLD_1_8) != HAL_OK)
  {
    Error_Handler();
  }
  if (HAL_UARTEx_SetRxFifoThreshold(&huart6, UART_RXFIFO_THRESHOLD_1_8) != HAL_OK)
  {
    Error_Handler();
  }
  if (HAL_UARTEx_DisableFifoMode(&huart6) != HAL_OK)
  {
    Error_Handler();
  }

}

static void MX_DMA_Init(void)
{

  /* DMA controller clock enable */
  __HAL_RCC_DMA1_CLK_ENABLE();

  /* DMA interrupt init */
  /* DMA1_Stream1_IRQn interrupt configuration */
  HAL_NVIC_SetPriority(DMA1_Stream1_IRQn, 5, 0);
  HAL_NVIC_EnableIRQ(DMA1_Stream1_IRQn);
  /* DMA1_Stream2_IRQn interrupt configuration */
  HAL_NVIC_SetPriority(DMA1_Stream2_IRQn, 5, 0);
  HAL_NVIC_EnableIRQ(DMA1_Stream2_IRQn);

}

static void MX_GPIO_Init(void)
{
  GPIO_InitTypeDef GPIO_InitStruct = {0};

  /* GPIO Ports Clock Enable */
  __HAL_RCC_GPIOK_CLK_ENABLE();
  __HAL_RCC_GPIOG_CLK_ENABLE();
  __HAL_RCC_GPIOA_CLK_ENABLE();
  __HAL_RCC_GPIOI_CLK_ENABLE();
  __HAL_RCC_GPIOB_CLK_ENABLE();
  __HAL_RCC_GPIOH_CLK_ENABLE();
  __HAL_RCC_GPIOC_CLK_ENABLE();
  __HAL_RCC_GPIOE_CLK_ENABLE();
  __HAL_RCC_GPIOD_CLK_ENABLE();
  __HAL_RCC_GPIOF_CLK_ENABLE();
  __HAL_RCC_GPIOJ_CLK_ENABLE();

  /*Configure GPIO pin Output Level */
  HAL_GPIO_WritePin(GPIOI, GPIO_PIN_0|GPIO_PIN_8|GPIO_PIN_10|GPIO_PIN_11, GPIO_PIN_RESET);

  /*Configure GPIO pin Output Level */
  HAL_GPIO_WritePin(GPIOE, GPIO_PIN_4|GPIO_PIN_3, GPIO_PIN_RESET);

  /*Configure GPIO pin Output Level */
  HAL_GPIO_WritePin(GPIOB, GPIO_PIN_8|GPIO_PIN_1|GPIO_PIN_0, GPIO_PIN_RESET);

  /*Configure GPIO pin Output Level */
  HAL_GPIO_WritePin(GPIOG, GPIO_PIN_15, GPIO_PIN_RESET);

  /*Configure GPIO pin Output Level */
  HAL_GPIO_WritePin(GPIOC, GPIO_PIN_13, GPIO_PIN_RESET);

  /*Configure GPIO pin Output Level */
  HAL_GPIO_WritePin(GPIOF, GPIO_PIN_3|GPIO_PIN_5|GPIO_PIN_13|GPIO_PIN_14
                          |GPIO_PIN_12, GPIO_PIN_RESET);

  /*Configure GPIO pin Output Level */
  HAL_GPIO_WritePin(GPIOJ, GPIO_PIN_0|GPIO_PIN_2|GPIO_PIN_3, GPIO_PIN_RESET);

  /*Configure GPIO pin : PK5 */
  GPIO_InitStruct.Pin = GPIO_PIN_5;
  GPIO_InitStruct.Mode = GPIO_MODE_INPUT;
  GPIO_InitStruct.Pull = GPIO_PULLDOWN;
  HAL_GPIO_Init(GPIOK, &GPIO_InitStruct);

  /*Configure GPIO pins : PG10 PG0 PG1 */
  GPIO_InitStruct.Pin = GPIO_PIN_10|GPIO_PIN_0|GPIO_PIN_1;
  GPIO_InitStruct.Mode = GPIO_MODE_INPUT;
  GPIO_InitStruct.Pull = GPIO_PULLDOWN;
  HAL_GPIO_Init(GPIOG, &GPIO_InitStruct);

  /*Configure GPIO pins : PA15 PA8 */
  GPIO_InitStruct.Pin = GPIO_PIN_15|GPIO_PIN_8;
  GPIO_InitStruct.Mode = GPIO_MODE_INPUT;
  GPIO_InitStruct.Pull = GPIO_NOPULL;
  HAL_GPIO_Init(GPIOA, &GPIO_InitStruct);

  /*Configure GPIO pins : PI0 PI8 PI10 PI11 */
  GPIO_InitStruct.Pin = GPIO_PIN_0|GPIO_PIN_8|GPIO_PIN_10|GPIO_PIN_11;
  GPIO_InitStruct.Mode = GPIO_MODE_OUTPUT_PP;
  GPIO_InitStruct.Pull = GPIO_NOPULL;
  GPIO_InitStruct.Speed = GPIO_SPEED_FREQ_LOW;
  HAL_GPIO_Init(GPIOI, &GPIO_InitStruct);

  /*Configure GPIO pin : PB4 */
  GPIO_InitStruct.Pin = GPIO_PIN_4;
  GPIO_InitStruct.Mode = GPIO_MODE_INPUT;
  GPIO_InitStruct.Pull = GPIO_NOPULL;
  HAL_GPIO_Init(GPIOB, &GPIO_InitStruct);

  /*Configure GPIO pins : PK4 PK2 PK0 */
  GPIO_InitStruct.Pin = GPIO_PIN_4|GPIO_PIN_2|GPIO_PIN_0;
  GPIO_InitStruct.Mode = GPIO_MODE_INPUT;
  GPIO_InitStruct.Pull = GPIO_NOPULL;
  HAL_GPIO_Init(GPIOK, &GPIO_InitStruct);

  /*Configure GPIO pins : PH14 PH13 */
  GPIO_InitStruct.Pin = GPIO_PIN_14|GPIO_PIN_13;
  GPIO_InitStruct.Mode = GPIO_MODE_INPUT;
  GPIO_InitStruct.Pull = GPIO_NOPULL;
  HAL_GPIO_Init(GPIOH, &GPIO_InitStruct);

  /*Configure GPIO pins : PE4 PE3 */
  GPIO_InitStruct.Pin = GPIO_PIN_4|GPIO_PIN_3;
  GPIO_InitStruct.Mode = GPIO_MODE_OUTPUT_PP;
  GPIO_InitStruct.Pull = GPIO_NOPULL;
  GPIO_InitStruct.Speed = GPIO_SPEED_FREQ_LOW;
  HAL_GPIO_Init(GPIOE, &GPIO_InitStruct);

  /*Configure GPIO pins : PB8 PB1 PB0 */
  GPIO_InitStruct.Pin = GPIO_PIN_8|GPIO_PIN_1|GPIO_PIN_0;
  GPIO_InitStruct.Mode = GPIO_MODE_OUTPUT_PP;
  GPIO_InitStruct.Pull = GPIO_NOPULL;
  GPIO_InitStruct.Speed = GPIO_SPEED_FREQ_LOW;
  HAL_GPIO_Init(GPIOB, &GPIO_InitStruct);

  /*Configure GPIO pin : PG15 */
  GPIO_InitStruct.Pin = GPIO_PIN_15;
  GPIO_InitStruct.Mode = GPIO_MODE_OUTPUT_PP;
  GPIO_InitStruct.Pull = GPIO_NOPULL;
  GPIO_InitStruct.Speed = GPIO_SPEED_FREQ_LOW;
  HAL_GPIO_Init(GPIOG, &GPIO_InitStruct);

  /*Configure GPIO pin : PC13 */
  GPIO_InitStruct.Pin = GPIO_PIN_13;
  GPIO_InitStruct.Mode = GPIO_MODE_OUTPUT_PP;
  GPIO_InitStruct.Pull = GPIO_NOPULL;
  GPIO_InitStruct.Speed = GPIO_SPEED_FREQ_LOW;
  HAL_GPIO_Init(GPIOC, &GPIO_InitStruct);

  /*Configure GPIO pins : PG7 PG5 PG4 PG3 */
  GPIO_InitStruct.Pin = GPIO_PIN_7|GPIO_PIN_5|GPIO_PIN_4|GPIO_PIN_3;
  GPIO_InitStruct.Mode = GPIO_MODE_INPUT;
  GPIO_InitStruct.Pull = GPIO_NOPULL;
  HAL_GPIO_Init(GPIOG, &GPIO_InitStruct);

  /*Configure GPIO pins : PF3 PF5 PF13 PF14
                           PF12 */
  GPIO_InitStruct.Pin = GPIO_PIN_3|GPIO_PIN_5|GPIO_PIN_13|GPIO_PIN_14
                          |GPIO_PIN_12;
  GPIO_InitStruct.Mode = GPIO_MODE_OUTPUT_PP;
  GPIO_InitStruct.Pull = GPIO_NOPULL;
  GPIO_InitStruct.Speed = GPIO_SPEED_FREQ_LOW;
  HAL_GPIO_Init(GPIOF, &GPIO_InitStruct);

  /*Configure GPIO pins : PF4 PF11 */
  GPIO_InitStruct.Pin = GPIO_PIN_4|GPIO_PIN_11;
  GPIO_InitStruct.Mode = GPIO_MODE_INPUT;
  GPIO_InitStruct.Pull = GPIO_PULLDOWN;
  HAL_GPIO_Init(GPIOF, &GPIO_InitStruct);

  /*Configure GPIO pins : PJ11 PJ10 PJ7 */
  GPIO_InitStruct.Pin = GPIO_PIN_11|GPIO_PIN_10|GPIO_PIN_7;
  GPIO_InitStruct.Mode = GPIO_MODE_INPUT;
  GPIO_InitStruct.Pull = GPIO_NOPULL;
  HAL_GPIO_Init(GPIOJ, &GPIO_InitStruct);

  /*Configure GPIO pins : PC2 PC3 */
  GPIO_InitStruct.Pin = GPIO_PIN_2|GPIO_PIN_3;
  GPIO_InitStruct.Mode = GPIO_MODE_INPUT;
  GPIO_InitStruct.Pull = GPIO_PULLDOWN;
  HAL_GPIO_Init(GPIOC, &GPIO_InitStruct);

  /*Configure GPIO pins : PH2 PH3 PH4 PH5
                           PH9 PH12 PH6 */
  GPIO_InitStruct.Pin = GPIO_PIN_2|GPIO_PIN_3|GPIO_PIN_4|GPIO_PIN_5
                          |GPIO_PIN_9|GPIO_PIN_12|GPIO_PIN_6;
  GPIO_InitStruct.Mode = GPIO_MODE_INPUT;
  GPIO_InitStruct.Pull = GPIO_PULLDOWN;
  HAL_GPIO_Init(GPIOH, &GPIO_InitStruct);

  /*Configure GPIO pin : PA0 */
  GPIO_InitStruct.Pin = GPIO_PIN_0;
  GPIO_InitStruct.Mode = GPIO_MODE_INPUT;
  GPIO_InitStruct.Pull = GPIO_PULLDOWN;
  HAL_GPIO_Init(GPIOA, &GPIO_InitStruct);

  /*Configure GPIO pins : PJ0 PJ2 PJ3 */
  GPIO_InitStruct.Pin = GPIO_PIN_0|GPIO_PIN_2|GPIO_PIN_3;
  GPIO_InitStruct.Mode = GPIO_MODE_OUTPUT_PP;
  GPIO_InitStruct.Pull = GPIO_NOPULL;
  GPIO_InitStruct.Speed = GPIO_SPEED_FREQ_LOW;
  HAL_GPIO_Init(GPIOJ, &GPIO_InitStruct);

  /*Configure GPIO pins : PJ6 PJ1 PJ5 PJ4 */
  GPIO_InitStruct.Pin = GPIO_PIN_6|GPIO_PIN_1|GPIO_PIN_5|GPIO_PIN_4;
  GPIO_InitStruct.Mode = GPIO_MODE_INPUT;
  GPIO_InitStruct.Pull = GPIO_PULLDOWN;
  HAL_GPIO_Init(GPIOJ, &GPIO_InitStruct);

  /*Configure GPIO pin : PI15 */
  GPIO_InitStruct.Pin = GPIO_PIN_15;
  GPIO_InitStruct.Mode = GPIO_MODE_INPUT;
  GPIO_InitStruct.Pull = GPIO_PULLDOWN;
  HAL_GPIO_Init(GPIOI, &GPIO_InitStruct);

  /*Configure GPIO pins : PE11 PE15 */
  GPIO_InitStruct.Pin = GPIO_PIN_11|GPIO_PIN_15;
  GPIO_InitStruct.Mode = GPIO_MODE_INPUT;
  GPIO_InitStruct.Pull = GPIO_NOPULL;
  HAL_GPIO_Init(GPIOE, &GPIO_InitStruct);

  /*Configure GPIO pins : PB10 PB11 PB2 */
  GPIO_InitStruct.Pin = GPIO_PIN_10|GPIO_PIN_11|GPIO_PIN_2;
  GPIO_InitStruct.Mode = GPIO_MODE_INPUT;
  GPIO_InitStruct.Pull = GPIO_PULLDOWN;
  HAL_GPIO_Init(GPIOB, &GPIO_InitStruct);

  /*Configure GPIO pins : PD15 PD11 */
  GPIO_InitStruct.Pin = GPIO_PIN_15|GPIO_PIN_11;
  GPIO_InitStruct.Mode = GPIO_MODE_INPUT;
  GPIO_InitStruct.Pull = GPIO_PULLDOWN;
  HAL_GPIO_Init(GPIOD, &GPIO_InitStruct);

  /*Configure GPIO pins : PD14 PD12 PD13 PD10 */
  GPIO_InitStruct.Pin = GPIO_PIN_14|GPIO_PIN_12|GPIO_PIN_13|GPIO_PIN_10;
  GPIO_InitStruct.Mode = GPIO_MODE_INPUT;
  GPIO_InitStruct.Pull = GPIO_NOPULL;
  HAL_GPIO_Init(GPIOD, &GPIO_InitStruct);

  /*Configure GPIO pin : PE12 */
  GPIO_InitStruct.Pin = GPIO_PIN_12;
  GPIO_InitStruct.Mode = GPIO_MODE_INPUT;
  GPIO_InitStruct.Pull = GPIO_PULLDOWN;
  HAL_GPIO_Init(GPIOE, &GPIO_InitStruct);

}

void StartMongooseTask(void *argument)
{
  /* USER CODE BEGIN 5 */
  run_mongoose();
  /* Infinite loop */
  for(;;)
  {
    osDelay(1);
  }
  /* USER CODE END 5 */
}

 /* MPU Configuration */

void MPU_Config(void)
{
  MPU_Region_InitTypeDef MPU_InitStruct = {0};

  /* Disables the MPU */
  HAL_MPU_Disable();

  /** Initializes and configures the Region and the memory to be protected
  */
  MPU_InitStruct.Enable = MPU_REGION_ENABLE;
  MPU_InitStruct.Number = MPU_REGION_NUMBER0;
  MPU_InitStruct.BaseAddress = 0x0;
  MPU_InitStruct.Size = MPU_REGION_SIZE_4GB;
  MPU_InitStruct.SubRegionDisable = 0x87;
  MPU_InitStruct.TypeExtField = MPU_TEX_LEVEL0;
  MPU_InitStruct.AccessPermission = MPU_REGION_NO_ACCESS;
  MPU_InitStruct.DisableExec = MPU_INSTRUCTION_ACCESS_DISABLE;
  MPU_InitStruct.IsShareable = MPU_ACCESS_SHAREABLE;
  MPU_InitStruct.IsCacheable = MPU_ACCESS_NOT_CACHEABLE;
  MPU_InitStruct.IsBufferable = MPU_ACCESS_NOT_BUFFERABLE;

  HAL_MPU_ConfigRegion(&MPU_InitStruct);
  /* Enables the MPU */
  HAL_MPU_Enable(MPU_PRIVILEGED_DEFAULT);

}

void HAL_TIM_PeriodElapsedCallback(TIM_HandleTypeDef *htim)
{
  if (htim->Instance == TIM6)
  {
    HAL_IncTick();
  }
}

void Error_Handler(void)
{
  __disable_irq();
  while (1)
  {
  }
}
